# nrf9230_engb_cellcore register map
Vendor: Nordic Semiconductor; Series: nRF92; File version: 1
CPU: CM33 r0p4, little endian, MPU, FPU, 3 interrupt priority bits, 480 interrupts, 8 SAU regions
Registers are 32-bit, read-write, reset 0x0 unless marked. A register's access mark holds for its fields unless they carry their own. Offsets are from the block's base; [hi:lo] are bit positions; lines under a group give offsets from that group; {n}, {i} and the like mark numbered series; 'fields as' and 'values as' point back to an identical list.

## SYSTEMTIMER_NS — Modem Timer/Counter 0
Base 0x44007000
Same registers: LTETIMER_NS 0x44022000, GNSSTIMER_NS 0x44033000, SYSTEMTIMER_S 0x54007000, LTETIMER_S 0x54022000, GNSSTIMER_S 0x54033000
0x00 TASKS_START wo — Start Timer
  [0] TASKS_START
    1=Trigger task
0x04 TASKS_STOP wo — Stop Timer
  [0] TASKS_STOP
    1=Trigger task
0x08 TASKS_CLEAR wo — Clear time
  [0] TASKS_CLEAR
    1=Trigger task
0x0C TASKS_SHUTDOWN wo — Shut down timer
  [0] TASKS_SHUTDOWN
    1=Trigger task
0x10 TASKS_STANDBY wo — Timer from shutdown to stopped state
  [0] TASKS_STANDBY
    1=Trigger task
0x14 TASKS_ADJUST wo — Adjust (increment or decrement) timer count by adjustment value
  [0] TASKS_ADJUST
    1=Trigger task
{0x40+4i} TASKS_CAPTURE[{i}] (i=0..7) wo — Description collection: Capture Timer value to CC[n] register
  [0] TASKS_CAPTURE — Capture Timer value to CC[n] register
    1=Trigger task
{0x100+4i} EVENTS_COMPARE[{i}] (i=0..7) — Description collection: Compare event on CC[n] match.
  [0] EVENTS_COMPARE — Compare event on CC[n] match.
    0=NotGenerated (Event not generated); 1=Generated (Event generated)
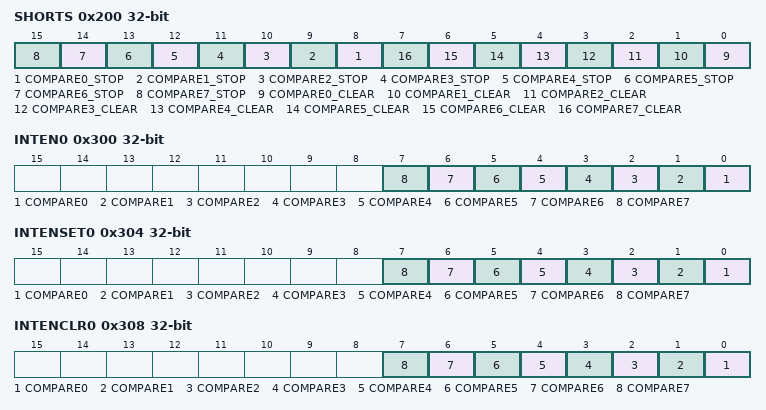
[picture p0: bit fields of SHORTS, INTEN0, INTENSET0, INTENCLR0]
0x200 SHORTS — Shortcuts between local events and tasks
  [all] fields
    0=Disabled (Disable shortcut); 1=Enabled (Enable shortcut)
  [n+8] COMPARE{n}_STOP (n=0..7) — Shortcut between event COMPARE[n] and task STOP
  [n] COMPARE{n}_CLEAR (n=0..7) — Shortcut between event COMPARE[n] and task CLEAR
0x300 INTEN0 — Enable or disable interrupt
  [all] fields
    0=Disabled; 1=Enabled
  [n] COMPARE{n} (n=0..7) — Enable or disable interrupt for event COMPARE[{n}]
0x304 INTENSET0 — Enable interrupt
  [all] fields
    on read: 0=Disabled (Read: Disabled); 1=Enabled (Read: Enabled) | on write: 1=Set (Enable)
  [n] COMPARE{n} (n=0..7) — Write '1' to enable interrupt for event COMPARE[{n}]
0x308 INTENCLR0 — Disable interrupt
  [all] fields
    on read: 0=Disabled (Read: Disabled); 1=Enabled (Read: Enabled) | on write: 1=Clear (Disable)
  [n] COMPARE{n} (n=0..7) — Write '1' to disable interrupt for event COMPARE[{n}]
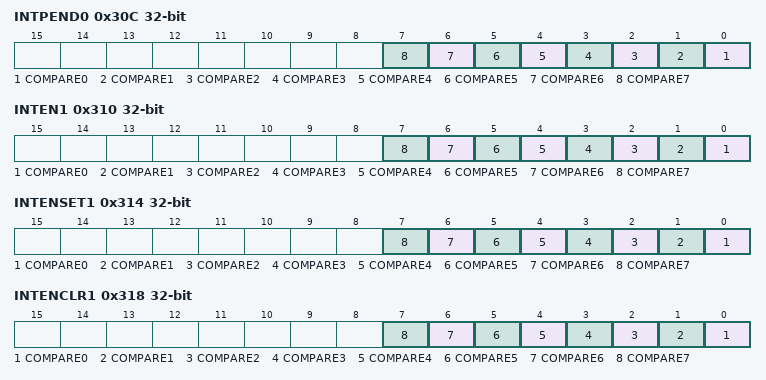
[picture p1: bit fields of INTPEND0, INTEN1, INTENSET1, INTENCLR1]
0x30C INTPEND0 ro — Pending interrupts
  [all] fields
    on read: 0=NotPending (Read: Not pending); 1=Pending (Read: Pending)
  [n] COMPARE{n} (n=0..7) — Read pending status of interrupt for event COMPARE[{n}]
0x310 INTEN1 — Enable or disable interrupt
  fields as INTEN0
0x314 INTENSET1 — Enable interrupt
  fields as INTENSET0
0x318 INTENCLR1 — Disable interrupt
  fields as INTENCLR0
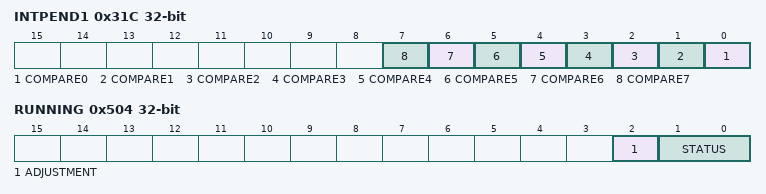
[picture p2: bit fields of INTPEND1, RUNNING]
0x31C INTPEND1 ro — Pending interrupts
  fields as INTPEND0
0x504 RUNNING ro — Status of running timer
  [2] ADJUSTMENT — Adjustment ongoing
    0=NORMAL_OPERATION (Normal operation, no events on hold.); 1=EVENTS_IN_HOLD (Compare events are on hold because of adjustment.)
  [1:0] STATUS — Current status
    0=SHUTDOWN (Timer is powered off.); 1=RUNNING (Timer is actively running.); 2=STOPPED (Timer is stopped.)
{0x540+8i} CC[{i}] (i=0..7) group — Capture/Compare register
  0x00 LO reset 0xFFFFFFFF — Description cluster: Capture/Compare register n - Low Word
    [31:0] CCLO — Capture/Compare value Low Word
  0x04 HI reset 0xFFFFFFFF — Description cluster: Capture/Compare register n - High Word
    [31:0] CCHI — Capture/Compare value High Word
0x580 COUNT group — Internal Counter Value
  0x00 LO wo — Internal Counter Value - Low Word
    [31:0] COUNTLO
  0x04 HI wo — Internal Counter Value - High Word
    [31:0] COUNTHI — Internal Counter Value High Word
0x588 COUNTRO group — Internal Counter Value - Read Only
  0x00 LO ro — Internal Counter Value - Read Only - Low Word
    [31:0] COUNTROLO
  0x04 HI ro — Internal Counter Value - Read Only - High Word
    [31:0] COUNTROHI
0x590 ADJUSTVALUE — Adjustment value for COUNT
  [15:0] ADJUSTVALUE

## Notices in the file
Copyright (c) 2010 - 2024, Nordic Semiconductor ASA
All rights reserved.
Redistribution and use in source and binary forms, with or without modification,
are permitted provided that the following conditions are met:
1. Redistributions of source code must retain the above copyright notice, this
list of conditions and the following disclaimer.
2. Redistributions in binary form, except as embedded into a Nordic
Semiconductor ASA integrated circuit in a product or a software update for
such product, must reproduce the above copyright notice, this list of
conditions and the following disclaimer in the documentation and/or other
materials provided with the distribution.
3. Neither the name of Nordic Semiconductor ASA nor the names of its
contributors may be used to endorse or promote products derived from this
software without specific prior written permission.
4. This software, with or without modification, must only be used with a
Nordic Semiconductor ASA integrated circuit.
5. Any software provided in binary form under this license must not be reverse
engineered, decompiled, modified and/or disassembled.
THIS SOFTWARE IS PROVIDED BY NORDIC SEMICONDUCTOR ASA "AS IS" AND ANY EXPRESS
OR IMPLIED WARRANTIES, INCLUDING, BUT NOT LIMITED TO, THE IMPLIED WARRANTIES
OF MERCHANTABILITY, NONINFRINGEMENT, AND FITNESS FOR A PARTICULAR PURPOSE ARE
DISCLAIMED. IN NO EVENT SHALL NORDIC SEMICONDUCTOR ASA OR CONTRIBUTORS BE
LIABLE FOR ANY DIRECT, INDIRECT, INCIDENTAL, SPECIAL, EXEMPLARY, OR
CONSEQUENTIAL DAMAGES (INCLUDING, BUT NOT LIMITED TO, PROCUREMENT OF SUBSTITUTE
GOODS OR SERVICES; LOSS OF USE, DATA, OR PROFITS; OR BUSINESS INTERRUPTION)
HOWEVER CAUSED AND ON ANY THEORY OF LIABILITY, WHETHER IN CONTRACT, STRICT
LIABILITY, OR TORT (INCLUDING NEGLIGENCE OR OTHERWISE) ARISING IN ANY WAY OUT
OF THE USE OF THIS SOFTWARE, EVEN IF ADVISED OF THE POSSIBILITY OF SUCH DAMAGE.
